# 3066H register map
File version: 1.0
Registers are 32-bit, access per field, reset 0x0 unless marked. A register's access mark holds for its fields unless they carry their own. Offsets are from the block's base; [hi:lo] are bit positions; {n}, {i} and the like mark numbered series.

## APT0 (part 2 of 2) — APT0 peripheral interface
Base 0x14A00000
Same registers: APT{n} {0x14A00000+0x1000*n} (n=1..15)
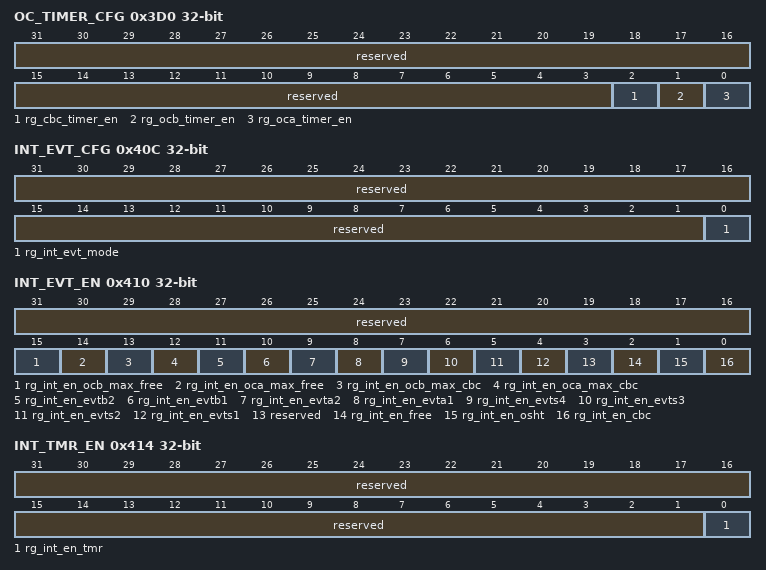
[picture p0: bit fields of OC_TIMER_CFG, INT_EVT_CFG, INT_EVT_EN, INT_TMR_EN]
0x3D0 OC_TIMER_CFG — OC_TIMER_CFG为保护计时器配置寄存器。支持写保护。
  [31:3] reserved ro — 保留。
  [2] rg_cbc_timer_en rw — CBC计时器使能。 0：不使能，OC_CBC_TIMER清零。 1：使能。OC_CBC_TIMER开始累计，当CBC保持0持续OC_CBC_TIMER_CLR后，OC_CBC_TIMER清零。
  [1] rg_ocb_timer_en rw — B路累计保护计时器使能。 0：不使能，OC_TIMER_B清零。 1：使能，OC_TIMER_B累计B路有效保护时间。
  [0] rg_oca_timer_en rw — A路累计保护计时器使能。 0：不使能，OC_TIMER_A清零。 1：使能，OC_TIMER_A累计A路有效保护时间。
0x3D4 OC_TIMER_A ro — OC_TIMER_A为APTx_PWMA累计保护计时器寄存器。
  [31:0] ro_oca_timer — A路累计的有效保护时间。记录因为保护导致PWM波发生变化的累计时间，包括输出1->0，输出0->1，输出0/1->高阻态。 0x0：累计保护持续了0个APTxCLK周期； 0x1：累计保护持续了1个APTxCLK周期； 0x2：累计保护持续了2个APTxCLK周期； … 0xFFFFFFFF：累计保护持续了大于等于4294967295个APTxCLK周期。
0x3D8 OC_TIMER_B ro — OC_TIMER_B为APTx_PWMB累计保护计时器寄存器。
  [31:0] ro_ocb_timer — B路累计的有效保护时间。记录因为保护导致PWM波发生变化的累计时间，包括输出1->0，输出0->1，输出0/1->高阻态。 0x0：累计保护持续了0个APTxCLK周期； 0x1：累计保护持续了1个APTxCLK周期； 0x2：累计保护持续了2个APTxCLK周期； … 0xFFFFFFFF：累计保护持续了大于等于4294967295个APTxCLK周期。
0x3DC OC_CBC_TIMER ro — OC_CBC_TIMER为CBC计时器寄存器。
  [31:0] ro_cbc_timer — CBC累计时间。累计CBC置位的时间。 0x0：累计CBC持续了0个APTxCLK周期； 0x1：累计CBC持续了1个APTxCLK周期； 0x2：累计CBC持续了2个APTxCLK周期； … 0xFFFFFFFF：累计CBC持续了大于等于4294967295个APTxCLK周期。
0x3E0 OC_CBC_TIMER_OSHT rw reset 0xFFFFFFFF — OC_CBC_TIMER_OSHT为CBC计时器配置寄存器。支持写保护。
  [31:0] rg_cbc_timer_osht — CBC计时器超过OC_CBC_TIMER_OSHT后，CBC无法被硬件周期性清零，只能由软件配置OC_SW_CLR清零。配置为0xFFFFFFFF时，不使能此功能。 0x0：0个APTxCLK周期； 0x1：1个APTxCLK周期； 0x2：2个APTxCLK周期； … 0xFFFFFFFE：4294967294个APTxCLK周期； 0xFFFFFFFF：不使能。
0x3E4 OC_CBC_TIMER_CLR rw reset 0xFFFFFFFF — OC_CBC_TIMER_CLR为CBC计时器自动清除配置寄存器。支持写保护。
  [31:0] rg_cbc_timer_clr — 当CBC保持0持续OC_CBC_TIMER_CLR后，OC_CBC_TIMER清零。配置为0xFFFFFFFF时，不使能此功能。 0x0：0个APTxCLK周期； 0x1：1个APTxCLK周期； 0x2：2个APTxCLK周期； … 0xFFFFFFFE：4294967294个APTxCLK周期； 0xFFFFFFFF：不清零。
0x40C INT_EVT_CFG — INT_EVT_CFG为事件中断配置寄存器。
  [31:1] reserved ro — 保留。
  [0] rg_int_evt_mode rw — 事件中断APTxEVTINT触发模式。本位域控制事件中断标志OC_EVT_FLAG触发置位的方式，进而改变APTxEVTINT触发模式。 0：上升沿触发； 1：高电平触发。
0x410 INT_EVT_EN — INT_EVT_EN为事件中断使能寄存器。
  [31:16] reserved ro — 保留。
  [15] rg_int_en_ocb_max_free rw — B路FREE最长保护事件中断使能。 0：OC_EVT_FLAG[ro_ocb_flag_max_free]不会触发事件中断APTxEVTINT； 1：OC_EVT_FLAG[ro_ocb_flag_max_free]会触发事件中断APTxEVTINT。
  [14] rg_int_en_oca_max_free rw — A路FREE最长保护事件中断使能。 0：OC_EVT_FLAG[ro_oca_flag_max_free]不会触发事件中断APTxEVTINT； 1：OC_EVT_FLAG[ro_oca_flag_max_free]会触发事件中断APTxEVTINT。
  [13] rg_int_en_ocb_max_cbc rw — B路CBC最长保护事件中断使能。 0：OC_EVT_FLAG[ro_ocb_flag_max_cbc]不会触发事件中断APTxEVTINT； 1：OC_EVT_FLAG[ro_ocb_flag_max_cbc]会触发事件中断APTxEVTINT。
  [12] rg_int_en_oca_max_cbc rw — A路CBC最长保护事件中断使能。 0：OC_EVT_FLAG[ro_oca_flag_max_cbc]不会触发事件中断APTxEVTINT； 1：OC_EVT_FLAG[ro_oca_flag_max_cbc]会触发事件中断APTxEVTINT。
  [11] rg_int_en_evtb2 rw — EMEVTB2事件中断使能。 0：OC_EVT_FLAG[ro_oc_flag_evtb2]不会触发事件中断APTxEVTINT； 1：OC_EVT_FLAG[ro_oc_flag_evtb2]会触发事件中断APTxEVTINT。
  [10] rg_int_en_evtb1 rw — EMEVTB1事件中断使能。 0：OC_EVT_FLAG[ro_oc_flag_evtb1]不会触发事件中断APTxEVTINT； 1：OC_EVT_FLAG[ro_oc_flag_evtb1]会触发事件中断APTxEVTINT。
  [9] rg_int_en_evta2 rw — EMEVTA2事件中断使能。 0：OC_EVT_FLAG[ro_oc_flag_evta2]不会触发事件中断APTxEVTINT； 1：OC_EVT_FLAG[ro_oc_flag_evta2]会触发事件中断APTxEVTINT。
  [8] rg_int_en_evta1 rw — EMEVTA1事件中断使能。 0：OC_EVT_FLAG[ro_oc_flag_evta1]不会触发事件中断APTxEVTINT； 1：OC_EVT_FLAG[ro_oc_flag_evta1]会触发事件中断APTxEVTINT。
  [7] rg_int_en_evts4 rw — SYSEVT4事件中断使能。 0：OC_EVT_FLAG[ro_oc_flag_evts4]不会触发事件中断APTxEVTINT； 1：OC_EVT_FLAG[ro_oc_flag_evts4]会触发事件中断APTxEVTINT。
  [6] rg_int_en_evts3 rw — SYSEVT3事件中断使能。 0：OC_EVT_FLAG[ro_oc_flag_evts3]不会触发事件中断APTxEVTINT； 1：OC_EVT_FLAG[ro_oc_flag_evts3]会触发事件中断APTxEVTINT。
  [5] rg_int_en_evts2 rw — SYSEVT2事件中断使能。 0：OC_EVT_FLAG[ro_oc_flag_evts2]不会触发事件中断APTxEVTINT； 1：OC_EVT_FLAG[ro_oc_flag_evts2]会触发事件中断APTxEVTINT。
  [4] rg_int_en_evts1 rw — SYSEVT1事件中断使能。 0：OC_EVT_FLAG[ro_oc_flag_evts1]不会触发事件中断APTxEVTINT； 1：OC_EVT_FLAG[ro_oc_flag_evts1]会触发事件中断APTxEVTINT。
  [3] reserved ro — 保留。
  [2] rg_int_en_free rw — FREE事件中断使能。 0：OC_EVT_FLAG[ro_oc_flag_free]不会触发事件中断APTxEVTINT； 1：OC_EVT_FLAG[ro_oc_flag_free]会触发事件中断APTxEVTINT。
  [1] rg_int_en_osht rw — OSHT事件中断使能。 0：OC_EVT_FLAG[ro_oc_flag_osht]不会触发事件中断APTxEVTINT； 1：OC_EVT_FLAG[ro_oc_flag_osht]会触发事件中断APTxEVTINT。
  [0] rg_int_en_cbc rw — CBC事件中断使能。 0：OC_EVT_FLAG[ro_oc_flag_cbc]不会触发事件中断APTxEVTINT； 1：OC_EVT_FLAG[ro_oc_flag_cbc]会触发事件中断APTxEVTINT。
0x414 INT_TMR_EN — INT_TMR_EN为定时中断使能寄存器。
  [31:1] reserved ro — 保留。
  [0] rg_int_en_tmr rw — 定时中断APTxTMRINT的使能位。 0：不使能； 1：使能。
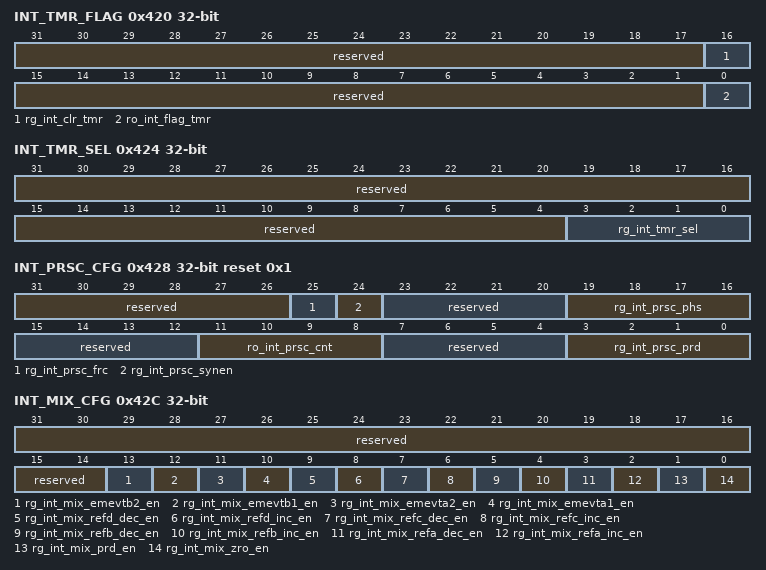
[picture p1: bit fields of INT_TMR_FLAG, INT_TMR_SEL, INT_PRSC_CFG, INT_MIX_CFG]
0x420 INT_TMR_FLAG — INT_TMR_FLAG为定时中断标志寄存器。
  [31:17] reserved ro — 保留。
  [16] rg_int_clr_tmr rw write-1-clears — 定时中断APTxTMRINT的中断清除位，写1清零。 0：写0无效； 1：写1有效。
  [15:1] reserved ro — 保留。
  [0] ro_int_flag_tmr ro — 定时中断APTxTMRINT的中断标志位。 0：APTxTMRINT无效； 1：APTxTMRINT有效。
0x424 INT_TMR_SEL — INT_TMR_SEL为定时中断的触发源选择寄存器。
  [31:4] reserved ro — 保留。
  [3:0] rg_int_tmr_sel rw — 定时中断APTxTMRINT的触发源选择。 0x1：CNT_ZERO有效； 0x2：CNT_PRD有效； 0x3：CNT_ZRO或CNT_PRD有效； 0x4：CNT_REFA有效且TCCNT计数方向递增； 0x5：CNT_REFA有效且TCCNT计数方向递减； 0x6：CNT_REFB有效且TCCNT计数方向递增； 0x7：CNT_REFB有效且TCCNT计数方向递减； 0x8：CNT_REFC有效且TCCNT计数方向递增； 0x9：CNT_REFC有效且TCCNT计数方向递减； 0xA：CNT_REFD有效且TCCNT计数方向递增； 0xB：CNT_REFD有效且TCCNT计数方向递减； 0xC：TMRINT_MIX有效； 其他：保留。
0x428 INT_PRSC_CFG reset 0x1 — INT_PRSC_CFG为定时中断缩减配置寄存器。
  [31:26] reserved ro — 保留。
  [25] rg_int_prsc_frc rw write-1-clears — 定时中断缩减计数器强制加1。 0：写0无效； 1：写1有效。
  [24] rg_int_prsc_synen rw — 定时中断缩减计数器的同步使能。 0：不使能； 1：使能。
  [23:20] reserved ro — 保留。
  [19:16] rg_int_prsc_phs rw — 定时中断缩减计数器的同步值。
  [15:12] reserved ro — 保留。
  [11:8] ro_int_prsc_cnt ro — 定时中断缩减计数器的计数值。
  [7:4] reserved ro — 保留。
  [3:0] rg_int_prsc_prd rw — 定时中断的缩减比例。 0x1：每发生1次有效的定时中断触发源，就产生定时中断； 0x2：每发生2次有效的定时中断触发源，就产生定时中断； 0x3：每发生3次有效的定时中断触发源，就产生定时中断； … 0xF：每发生15次有效的定时中断触发源，就产生定时中断。 其他：保留。
0x42C INT_MIX_CFG — INT_MIX_CFG为TMRINT_MIX配置寄存器。
  [31:14] reserved ro — 保留。
  [13] rg_int_mix_emevtb2_en rw — 使能EMEVTB2触发TMRINT_MIX信号。 0：不使能； 1：使能。
  [12] rg_int_mix_emevtb1_en rw — 使能EMEVTB1触发TMRINT_MIX信号。 0：不使能； 1：使能。
  [11] rg_int_mix_emevta2_en rw — 使能EMEVTA2触发TMRINT_MIX信号。 0：不使能； 1：使能。
  [10] rg_int_mix_emevta1_en rw — 使能EMEVTA1触发TMRINT_MIX信号。 0：不使能； 1：使能。
  [9] rg_int_mix_refd_dec_en rw — 使能CNT_REFD有效且TCCNT计数方向递减触发TMRINT_MIX信号。 0：不使能； 1：使能。
  [8] rg_int_mix_refd_inc_en rw — 使能CNT_REFD有效且TCCNT计数方向递增触发TMRINT_MIX信号。 0：不使能； 1：使能。
  [7] rg_int_mix_refc_dec_en rw — 使能CNT_REFC有效且TCCNT计数方向递减触发TMRINT_MIX信号。 0：不使能； 1：使能。
  [6] rg_int_mix_refc_inc_en rw — 使能CNT_REFC有效且TCCNT计数方向递增触发TMRINT_MIX信号。 0：不使能； 1：使能。
  [5] rg_int_mix_refb_dec_en rw — 使能CNT_REFB有效且TCCNT计数方向递减触发TMRINT_MIX信号。 0：不使能； 1：使能。
  [4] rg_int_mix_refb_inc_en rw — 使能CNT_REFB有效且TCCNT计数方向递增触发TMRINT_MIX信号。 0：不使能； 1：使能。
  [3] rg_int_mix_refa_dec_en rw — 使能CNT_REFA有效且TCCNT计数方向递减触发TMRINT_MIX信号。 0：不使能； 1：使能。
  [2] rg_int_mix_refa_inc_en rw — 使能CNT_REFA有效且TCCNT计数方向递增触发TMRINT_MIX信号。 0：不使能； 1：使能。
  [1] rg_int_mix_prd_en rw — 使能CNT_PRD触发TMRINT_MIX信号。 0：不使能； 1：使能。
  [0] rg_int_mix_zro_en rw — 使能CNT_ZERO触发TMRINT_MIX信号。 0：不使能； 1：使能。
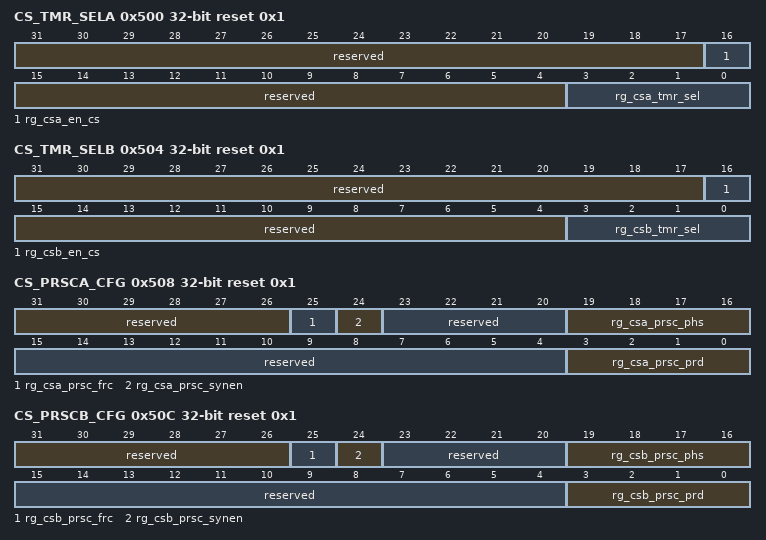
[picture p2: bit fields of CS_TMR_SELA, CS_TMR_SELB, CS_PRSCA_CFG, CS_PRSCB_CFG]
0x500 CS_TMR_SELA reset 0x1 — CS_TMR_SELA为APTxSOCA的触发源选择寄存器。
  [31:17] reserved ro — 保留。
  [16] rg_csa_en_cs rw — APTxSOCA的使能位。 0：不使能； 1：使能。
  [15:4] reserved ro — 保留。
  [3:0] rg_csa_tmr_sel rw — APTxSOCA的触发源选择。 0x0：EMEVTA1有效； 0x1：CNT_ZERO有效； 0x2：CNT_PRD有效； 0x3：CNT_ZERO或CNT_PRD有效； 0x4：CNT_REFA有效且TCCNT计数方向递增； 0x5：CNT_REFA有效且TCCNT计数方向递减； 0x6：CNT_REFB有效且TCCNT计数方向递增； 0x7：CNT_REFB有效且TCCNT计数方向递减； 0x8：CNT_REFC有效且TCCNT计数方向递增； 0x9：CNT_REFC有效且TCCNT计数方向递减； 0xA：CNT_REFD有效且TCCNT计数方向递增； 0xB：CNT_REFD有效且TCCNT计数方向递减； 0xC：SOCA_MIX有效； 其他：保留。
0x504 CS_TMR_SELB reset 0x1 — CS_TMR_SELB为APTxSOCB的触发源选择寄存器。
  [31:17] reserved ro — 保留。
  [16] rg_csb_en_cs rw — APTxSOCB的使能位。 0：不使能； 1：使能。
  [15:4] reserved ro — 保留。
  [3:0] rg_csb_tmr_sel rw — APTxSOCB的触发源选择。 0x0：EMEVTB1有效； 0x1：CNT_ZERO有效； 0x2：CNT_PRD有效； 0x3：CNT_ZERO或CNT_PRD有效； 0x4：CNT_REFA有效且TCCNT计数方向递增； 0x5：CNT_REFA有效且TCCNT计数方向递减； 0x6：CNT_REFB有效且TCCNT计数方向递增； 0x7：CNT_REFB有效且TCCNT计数方向递减； 0x8：CNT_REFC有效且TCCNT计数方向递增； 0x9：CNT_REFC有效且TCCNT计数方向递减； 0xA：CNT_REFD有效且TCCNT计数方向递增； 0xB：CNT_REFD有效且TCCNT计数方向递减； 0xC：SOCB_MIX有效； 其他：保留。
0x508 CS_PRSCA_CFG reset 0x1 — CS_PRSCA_CFG为APTxSOCA缩减配置寄存器。
  [31:26] reserved ro — 保留。
  [25] rg_csa_prsc_frc rw write-1-clears — APTxSOCA缩减计数器强制加1。 0：写0无效； 1：写1有效。
  [24] rg_csa_prsc_synen rw — APTxSOCA缩减计数器的同步使能。 0：不使能； 1：使能。
  [23:20] reserved ro — 保留。
  [19:16] rg_csa_prsc_phs rw — APTxSOCA缩减计数器的同步值。
  [15:4] reserved ro — 保留。
  [3:0] rg_csa_prsc_prd rw — APTxSOCA的缩减比例。 0x1：每发生1次有效的APTxSOCA的触发源，就产生APTxSOCA； 0x2：每发生2次有效的APTxSOCA的触发源，就产生APTxSOCA； 0x3：每发生3次有效的APTxSOCA的触发源，就产生APTxSOCA； … 0xF：每发生15次有效的APTxSOCA的触发源，就产生APTxSOCA。 其他：保留。
0x50C CS_PRSCB_CFG reset 0x1 — CS_PRSCB_CFG为APTxSOCB缩减配置寄存器。
  [31:26] reserved ro — 保留。
  [25] rg_csb_prsc_frc rw write-1-clears — APTxSOCB缩减计数器强制加1。 0：写0无效； 1：写1有效。
  [24] rg_csb_prsc_synen rw — APTxSOCB缩减计数器的同步使能。 0：不使能； 1：使能。
  [23:20] reserved ro — 保留。
  [19:16] rg_csb_prsc_phs rw — APTxSOCB缩减计数器的同步值。
  [15:4] reserved ro — 保留。
  [3:0] rg_csb_prsc_prd rw — APTxSOCB的缩减比例。 0x1：每发生1次有效的APTxSOCB的触发源，就产生APTxSOCB； 0x2：每发生2次有效的APTxSOCB的触发源，就产生APTxSOCB； 0x3：每发生3次有效的APTxSOCB的触发源，就产生APTxSOCB； … 0xF：每发生15次有效的APTxSOCB的触发源，就产生APTxSOCB。 其他：保留。
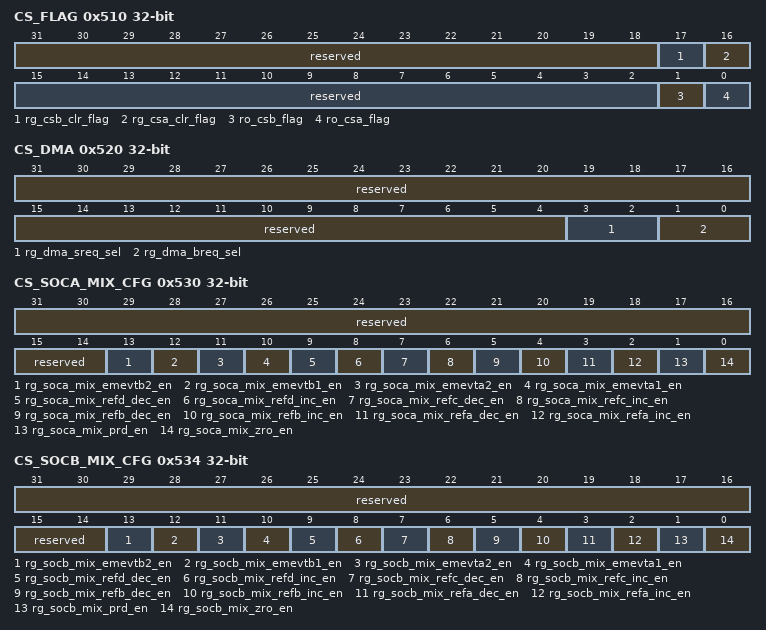
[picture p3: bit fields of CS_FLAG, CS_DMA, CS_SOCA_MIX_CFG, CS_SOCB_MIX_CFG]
0x510 CS_FLAG — CS_FLAG为APTxSOCA/APTxSOCB标志寄存器。
  [31:18] reserved ro — 保留。
  [17] rg_csb_clr_flag rw write-1-clears — APTxSOCB标志清除位，写1清零。 0：写0无效； 1：写1有效。
  [16] rg_csa_clr_flag rw write-1-clears — APTxSOCA标志清除位，写1清零。 0：写0无效； 1：写1有效。
  [15:2] reserved ro — 保留。
  [1] ro_csb_flag ro — APTxSOCB的标志位。 0：没有产生APTxSOCB； 1：已经产生APTxSOCB。
  [0] ro_csa_flag ro — APTxSOCA的标志位。 0：没有产生APTxSOCA； 1：已经产生APTxSOCA。
0x520 CS_DMA — CS_DMA为DMA请求配置寄存器。
  [31:4] reserved ro — 保留。
  [3:2] rg_dma_sreq_sel rw — DMA Single请求的触发源选择。 01：TRIGA信号有效； 10：TRIGB信号有效； 其他：禁止产生DMA Single请求。
  [1:0] rg_dma_breq_sel rw — DMA Burst请求的源头选择。 01：TRIGA信号有效； 10：TRIGB信号有效； 其他：禁止产生DMA Burst请求。
0x530 CS_SOCA_MIX_CFG — CS_SOCA_MIX_CFG为SOCA_MIX配置寄存器。
  [31:14] reserved ro — 保留。
  [13] rg_soca_mix_emevtb2_en rw — 使能EMEVTB2触发SOCA_MIX信号。 0：不使能； 1：使能。
  [12] rg_soca_mix_emevtb1_en rw — 使能EMEVTB1触发SOCA_MIX信号。 0：不使能； 1：使能。
  [11] rg_soca_mix_emevta2_en rw — 使能EMEVTA2触发SOCA_MIX信号。 0：不使能； 1：使能。
  [10] rg_soca_mix_emevta1_en rw — 使能EMEVTA1触发SOCA_MIX信号。 0：不使能； 1：使能。
  [9] rg_soca_mix_refd_dec_en rw — 使能CNT_REFD有效且TCCNT计数方向递减触发SOCA_MIX信号。 0：不使能； 1：使能。
  [8] rg_soca_mix_refd_inc_en rw — 使能CNT_REFD有效且TCCNT计数方向递增触发SOCA_MIX信号。 0：不使能； 1：使能。
  [7] rg_soca_mix_refc_dec_en rw — 使能CNT_REFC有效且TCCNT计数方向递减触发SOCA_MIX信号。 0：不使能； 1：使能。
  [6] rg_soca_mix_refc_inc_en rw — 使能CNT_REFC有效且TCCNT计数方向递增触发SOCA_MIX信号。 0：不使能； 1：使能。
  [5] rg_soca_mix_refb_dec_en rw — 使能CNT_REFB有效且TCCNT计数方向递减触发SOCA_MIX信号。 0：不使能； 1：使能。
  [4] rg_soca_mix_refb_inc_en rw — 使能CNT_REFB有效且TCCNT计数方向递增触发SOCA_MIX信号。 0：不使能； 1：使能。
  [3] rg_soca_mix_refa_dec_en rw — 使能CNT_REFA有效且TCCNT计数方向递减触发SOCA_MIX信号。 0：不使能； 1：使能。
  [2] rg_soca_mix_refa_inc_en rw — 使能CNT_REFA有效且TCCNT计数方向递增触发SOCA_MIX信号。 0：不使能； 1：使能。
  [1] rg_soca_mix_prd_en rw — 使能CNT_PRD触发SOCA_MIX信号。 0：不使能； 1：使能。
  [0] rg_soca_mix_zro_en rw — 使能CNT_ZERO触发SOCA_MIX信号。 0：不使能； 1：使能。
0x534 CS_SOCB_MIX_CFG — CS_SOCB_MIX_CFG为SOCB_MIX配置寄存器。
  [31:14] reserved ro — 保留。
  [13] rg_socb_mix_emevtb2_en rw — 使能EMEVTB2触发SOCB_MIX信号。 0：不使能； 1：使能。
  [12] rg_socb_mix_emevtb1_en rw — 使能EMEVTB1触发SOCB_MIX信号。 0：不使能； 1：使能。
  [11] rg_socb_mix_emevta2_en rw — 使能EMEVTA2触发SOCB_MIX信号。 0：不使能； 1：使能。
  [10] rg_socb_mix_emevta1_en rw — 使能EMEVTA1触发SOCB_MIX信号。 0：不使能； 1：使能。
  [9] rg_socb_mix_refd_dec_en rw — 使能CNT_REFD有效且TCCNT计数方向递减触发SOCB_MIX信号。 0：不使能； 1：使能。
  [8] rg_socb_mix_refd_inc_en rw — 使能CNT_REFD有效且TCCNT计数方向递增触发SOCB_MIX信号。 0：不使能； 1：使能。
  [7] rg_socb_mix_refc_dec_en rw — 使能CNT_REFC有效且TCCNT计数方向递减触发SOCB_MIX信号。 0：不使能； 1：使能。
  [6] rg_socb_mix_refc_inc_en rw — 使能CNT_REFC有效且TCCNT计数方向递增触发SOCB_MIX信号。 0：不使能； 1：使能。
  [5] rg_socb_mix_refb_dec_en rw — 使能CNT_REFB有效且TCCNT计数方向递减触发SOCB_MIX信号。 0：不使能； 1：使能。
  [4] rg_socb_mix_refb_inc_en rw — 使能CNT_REFB有效且TCCNT计数方向递增触发SOCB_MIX信号。 0：不使能； 1：使能。
  [3] rg_socb_mix_refa_dec_en rw — 使能CNT_REFA有效且TCCNT计数方向递减触发SOCB_MIX信号。 0：不使能； 1：使能。
  [2] rg_socb_mix_refa_inc_en rw — 使能CNT_REFA有效且TCCNT计数方向递增触发SOCB_MIX信号。 0：不使能； 1：使能。
  [1] rg_socb_mix_prd_en rw — 使能CNT_PRD触发SOCB_MIX信号。 0：不使能； 1：使能。
  [0] rg_socb_mix_zro_en rw — 使能CNT_ZERO触发SOCB_MIX信号。 0：不使能； 1：使能。
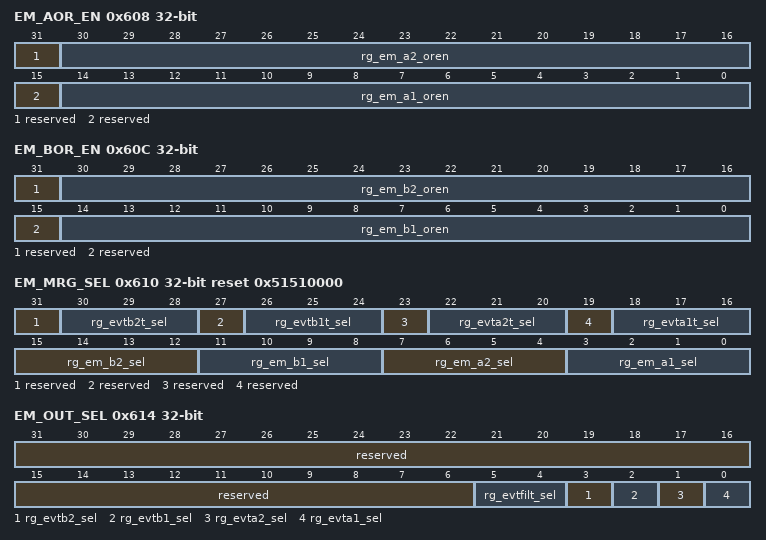
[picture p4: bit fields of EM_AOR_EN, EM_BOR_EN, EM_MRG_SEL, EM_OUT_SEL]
0x608 EM_AOR_EN — EM_AOR_EN为事件管理组合输入选择寄存器A。支持写保护。
  [31] reserved ro — 保留。
  [30:16] rg_em_a2_oren rw — TRIP_OR_A2的触发源选择，每个比特对应一个信号。 bit[30]：代表TRIP15的使能位； bit[29]：代表TRIP14的使能位； bit[28]：代表TRIP13的使能位； bit[27]：代表TRIP12的使能位； bit[26]：代表TRIP11的使能位； bit[25]：代表TRIP10的使能位； bit[24]：代表TRIP9的使能位； bit[23]：代表TRIP8的使能位； bit[22]：代表TRIP7的使能位； bit[21]：代表TRIP6的使能位； bit[20]：代表TRIP5的使能位； bit[19]：代表TRIP4的使能位； bit[18]：代表TRIP3的使能位； bit[17]：代表TRIP2的使能位； bit[16]：代表TRIP1的使能位； 其他比特无效，应配置为0。 当相应的比特为1时，代表对应的信号参与逻辑或； 当相应的比特为0时，代表对应的信号不参与逻辑或。
  [15] reserved ro — 保留。
  [14:0] rg_em_a1_oren rw — TRIP_OR_A1的触发源选择，每个比特对应一个信号。 bit[14]：代表TRIP15的使能位； bit[13]：代表TRIP14的使能位； bit[12]：代表TRIP13的使能位； bit[11]：代表TRIP12的使能位； bit[10]：代表TRIP11的使能位； bit[9]：代表TRIP10的使能位； bit[8]：代表TRIP9的使能位； bit[7]：代表TRIP8的使能位； bit[6]：代表TRIP7的使能位； bit[5]：代表TRIP6的使能位； bit[4]：代表TRIP5的使能位； bit[3]：代表TRIP4的使能位； bit[2]：代表TRIP3的使能位； bit[1]：代表TRIP2的使能位； bit[0]：代表TRIP1的使能位； 其他比特无效，应配置为0。 当相应的比特为1时，代表对应的信号参与逻辑或； 当相应的比特为0时，代表对应的信号不参与逻辑或。
0x60C EM_BOR_EN — EM_BOR_EN为事件管理组合输入选择寄存器B。支持写保护。
  [31] reserved ro — 保留。
  [30:16] rg_em_b2_oren rw — TRIP_OR_B2的触发源选择，每个比特对应一个信号。 bit[30]：代表TRIP15的使能位； bit[29]：代表TRIP14的使能位； bit[28]：代表TRIP13的使能位； bit[27]：代表TRIP12的使能位； bit[26]：代表TRIP11的使能位； bit[25]：代表TRIP10的使能位； bit[24]：代表TRIP9的使能位； bit[23]：代表TRIP8的使能位； bit[22]：代表TRIP7的使能位； bit[21]：代表TRIP6的使能位； bit[20]：代表TRIP5的使能位； bit[19]：代表TRIP4的使能位； bit[18]：代表TRIP3的使能位； bit[17]：代表TRIP2的使能位； bit[16]：代表TRIP1的使能位；其他比特无效，应配置为0。 当相应的比特为1时，代表对应的信号参与逻辑或； 当相应的比特为0时，代表对应的信号不参与逻辑或。
  [15] reserved ro — 保留。
  [14:0] rg_em_b1_oren rw — TRIP_OR_B1的触发源选择，每个比特对应一个信号。 bit[14]：代表TRIP15的使能位； bit[13]：代表TRIP14的使能位； bit[12]：代表TRIP13的使能位； bit[11]：代表TRIP12的使能位； bit[10]：代表TRIP11的使能位； bit[9]：代表TRIP10的使能位； bit[8]：代表TRIP9的使能位； bit[7]：代表TRIP8的使能位； bit[6]：代表TRIP7的使能位； bit[5]：代表TRIP6的使能位； bit[4]：代表TRIP5的使能位； bit[3]：代表TRIP4的使能位； bit[2]：代表TRIP3的使能位； bit[1]：代表TRIP2的使能位； bit[0]：代表TRIP1的使能位；其他比特无效，应配置为0。 当相应的比特为1时，代表对应的信号参与逻辑或； 当相应的比特为0时，代表对应的信号不参与逻辑或。
0x610 EM_MRG_SEL reset 0x51510000 — EM_MRG_SEL为事件管理输入选择寄存器。支持写保护。
  [31] reserved ro — 保留。
  [30:28] rg_evtb2t_sel rw — EMEVTB2_TEMP有效（高电平有效）的条件选择。 0x1：EMEVTB1_SRC为高电平； 0x2：EMEVTB1_SRC为高电平，且EMEVTB2_SRC为低电平； 0x3：EMEVTB1_SRC为高电平，且EMEVTB2_SRC为高电平； 0x4：EMEVTB1_SRC为低电平，且EMEVTB2_SRC为高电平； 0x5：EMEVTB2_SRC为高电平； 其他：EMEVTB2_TEMP输出低电平。
  [27] reserved ro — 保留。
  [26:24] rg_evtb1t_sel rw — EMEVTB1_TEMP有效（高电平有效）的条件选择。 0x1：EMEVTB1_SRC为高电平； 0x2：EMEVTB1_SRC为高电平，且EMEVTB2_SRC为低电平； 0x3：EMEVTB1_SRC为高电平，且EMEVTB2_SRC为高电平； 0x4：EMEVTB1_SRC为低电平，且EMEVTB2_SRC为高电平； 0x5：EMEVTB2_SRC为高电平； 其他：EMEVTB1_TEMP输出低电平。
  [23] reserved ro — 保留。
  [22:20] rg_evta2t_sel rw — EMEVTA2_TEMP有效（高电平有效）的条件选择。 0x1：EMEVTA1_SRC为高电平； 0x2：EMEVTA1_SRC为高电平，且EMEVTA2_SRC为低电平； 0x3：EMEVTA1_SRC为高电平，且EMEVTA2_SRC为高电平； 0x4：EMEVTA1_SRC为低电平，且EMEVTA2_SRC为高电平； 0x5：EMEVTA2_SRC为高电平； 其他：EMEVTA2_TEMP输出低电平。
  [19] reserved ro — 保留。
  [18:16] rg_evta1t_sel rw — EMEVTA1_TEMP有效（高电平有效）的条件选择。 0x1：EMEVTA1_SRC为高电平； 0x2：EMEVTA1_SRC为高电平，且EMEVTA2_SRC为低电平； 0x3：EMEVTA1_SRC为高电平，且EMEVTA2_SRC为高电平； 0x4：EMEVTA1_SRC为低电平，且EMEVTA2_SRC为高电平； 0x5：EMEVTA2_SRC为高电平； 其他：EMEVTA1_TEMP输出低电平。
  [15:12] rg_em_b2_sel rw — EMEVTB2_SRC触发源选择。 0x0：TRIP1； 0x1：TRIP2； 0x2：TRIP3； 0x3：TRIP4； 0x4：TRIP5； 0x5：TRIP6； 0x6：TRIP7； 0x7：TRIP8； 0x8：TRIP9； 0x9：TRIP10； 0xA：TRIP11； 0xB：TRIP12； 0xC：TRIP13； 0xD：TRIP14； 0xE：TRIP15； 0xF：TRIP_OR_B2； 其他：EMEVTB2_SRC输出低电平。
  [11:8] rg_em_b1_sel rw — EMEVTB1_SRC触发源选择。 0x0：TRIP1； 0x1：TRIP2； 0x2：TRIP3； 0x3：TRIP4； 0x4：TRIP5； 0x5：TRIP6； 0x6：TRIP7； 0x7：TRIP8； 0x8：TRIP9； 0x9：TRIP10； 0xA：TRIP11； 0xB：TRIP12； 0xC：TRIP13； 0xD：TRIP14； 0xE：TRIP15； 0xF：TRIP_OR_B1； 其他：EMEVTB1_SRC输出低电平。
  [7:4] rg_em_a2_sel rw — EMEVTA2_SRC触发源选择。 0x0：TRIP1； 0x1：TRIP2； 0x2：TRIP3； 0x3：TRIP4； 0x4：TRIP5； 0x5：TRIP6； 0x6：TRIP7； 0x7：TRIP8； 0x8：TRIP9； 0x9：TRIP10； 0xA：TRIP11； 0xB：TRIP12； 0xC：TRIP13； 0xD：TRIP14； 0xE：TRIP15； 0xF：TRIP_OR_A2； 其他：EMEVTA2_SRC输出低电平。
  [3:0] rg_em_a1_sel rw — EMEVTA1_SRC触发源选择。 0x0：TRIP1； 0x1：TRIP2； 0x2：TRIP3； 0x3：TRIP4； 0x4：TRIP5； 0x5：TRIP6； 0x6：TRIP7； 0x7：TRIP8； 0x8：TRIP9； 0x9：TRIP10； 0xA：TRIP11； 0xB：TRIP12； 0xC：TRIP13； 0xD：TRIP14； 0xE：TRIP15； 0xF：TRIP_OR_A1； 其他：EMEVTA1_SRC输出低电平。
0x614 EM_OUT_SEL — EM_OUT_SEL为事件管理输出选择寄存器。支持写保护。
  [31:6] reserved ro — 保留。
  [5:4] rg_evtfilt_sel rw — EMEVTFILT的触发源选择。 00：EMEVTA1_TEMP； 01：EMEVTA2_TEMP； 10：EMEVTB1_TEMP； 11：EMEVTB2_TEMP。
  [3] rg_evtb2_sel rw — EMEVTB2的触发源选择。 0：EMEVTB2_TEMP； 1：EMEVTFILT。
  [2] rg_evtb1_sel rw — EMEVTB1的触发源选择。 0：EMEVTB1_TEMP； 1：EMEVTFILT。
  [1] rg_evta2_sel rw — EMEVTA2的触发源选择。 0：EMEVTA2_TEMP； 1：EMEVTFILT。
  [0] rg_evta1_sel rw — EMEVTA1的触发源选择。 0：EMEVTA1_TEMP； 1：EMEVTFILT。
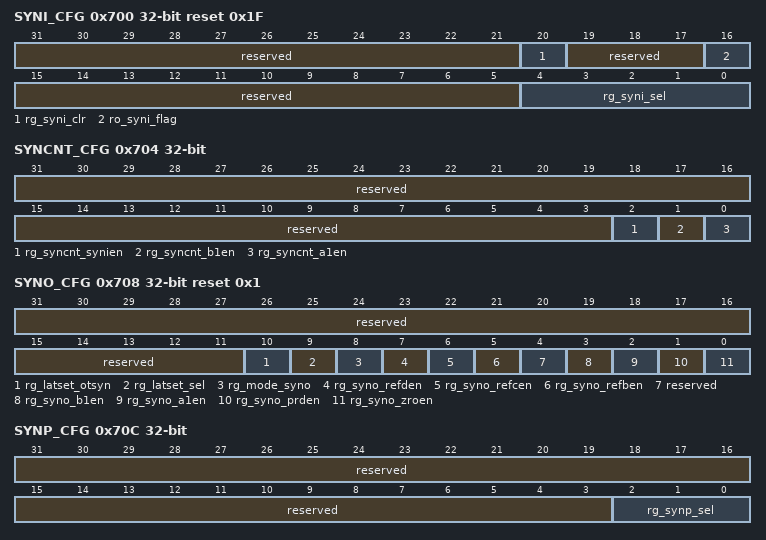
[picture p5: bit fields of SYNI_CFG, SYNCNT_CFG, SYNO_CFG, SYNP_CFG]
0x700 SYNI_CFG reset 0x1F — SYNI_CFG为同步输入配置寄存器。
  [31:21] reserved ro — 保留。
  [20] rg_syni_clr rw write-1-clears — APTxSYNCI的标志清除位，写1清零。 0：写0无效； 1：写1清除APTxSYNCI的标志位ro_syni_flag。
  [19:17] reserved ro — 保留。
  [16] ro_syni_flag ro — APTxSYNCI的标志位。 0：APTxSYNCI无效； 1：APTxSYNCI有效。
  [15:5] reserved ro — 保留。
  [4:0] rg_syni_sel rw — APTxSYNCI的触发源选择。 0x0：APT0SYNCO； 0x1：APT1SYNCO； 0x2：APT2SYNCO； 0x3：APT3SYNCO； 0x4：APT4SYNCO； 0x5：APT5SYNCO； 0x6：APT6SYNCO； 0x7：APT7SYNCO； 0x8：APT8SYNCO； 0x9：CAPM0SYNCO； 0xA：CAPM1SYNCO； 0xB：CAPM2SYNCO； 0xC：TRIP4； 0xD：TRIP5； 0xE：APT9SYNCO； 0xF：APT10SYNCO； 0x10：APT11SYNCO； 0x11：APT12SYNCO； 0x12：APT13SYNCO； 0x13：APT14SYNCO； 0x14：APT15SYNCO； 其他：禁止产生APTxSYNCI。
0x704 SYNCNT_CFG — SYNCNT_CFG为计数器同步信号配置寄存器。
  [31:3] reserved ro — 保留。
  [2] rg_syncnt_synien rw — 当APTxSYNCI有效时，选择是否产生APTCNTSYNC。 0：不使能； 1：使能。
  [1] rg_syncnt_b1en rw — 当EMEVTB1有效时，选择是否产生APTCNTSYNC。 0：不使能； 1：使能。
  [0] rg_syncnt_a1en rw — 当EMEVTA1有效时，选择是否产生APTCNTSYNC。 0：不使能； 1：使能。
0x708 SYNO_CFG reset 0x1 — SYNO_CFG为同步输出配置寄存器。
  [31:11] reserved ro — 保留。
  [10] rg_latset_otsyn rw write-1-clears — 控制同步输出单次锁存器置位。 0：写0无效； 1：写1有效。
  [9] rg_latset_sel rw — 当选择单次同步输出模式，选择同步输出单次锁存器置位的条件。 0：向SYNO_CFG[rg_latset_otsyn]写1时置位； 1：向GLB_LOAD[rg_latset_otgld]写1时置位。
  [8] rg_mode_syno rw — 同步输出的模式选择。 0：单次同步输出； 1：不限次数同步输出。
  [7] rg_syno_refden rw — 当CNT_REFD有效时，选择是否产生APTxSYNCO。 0：不使能； 1：使能。
  [6] rg_syno_refcen rw — 当CNT_REFC有效时，选择是否产生APTxSYNCO。 0：不使能； 1：使能。
  [5] rg_syno_refben rw — 当CNT_REFB有效时，选择是否产生APTxSYNCO。 0：不使能； 1：使能。
  [4] reserved ro — 保留。
  [3] rg_syno_b1en rw — 当EMEVTB1有效时，选择是否产生APTxSYNCO。 0：不使能； 1：使能。
  [2] rg_syno_a1en rw — 当EMEVTA1有效时，选择是否产生APTxSYNCO。 0：不使能； 1：使能。
  [1] rg_syno_prden rw — 当CNT_PRD有效时，选择是否产生APTxSYNCO。 0：不使能； 1：使能。
  [0] rg_syno_zroen rw — 当CNT_ZERO有效时，选择是否产生APTxSYNCO。 0：不使能； 1：使能。
0x70C SYNP_CFG — SYNP_CFG为外设同步配置寄存器。
  [31:3] reserved ro — 保留。
  [2:0] rg_synp_sel rw — 外设同步输出的源头选择。 000：禁止； 001：TC计数器等于0； 010：TC计数器等于计数周期； 011：TC计数器等于计数参考值C，且计数方向递增； 100：TC计数器等于计数参考值C，且计数方向递减； 101：TC计数器等于计数参考值D，且计数方向递增； 110：TC计数器等于计数参考值D，且计数方向递减； 111：禁止。
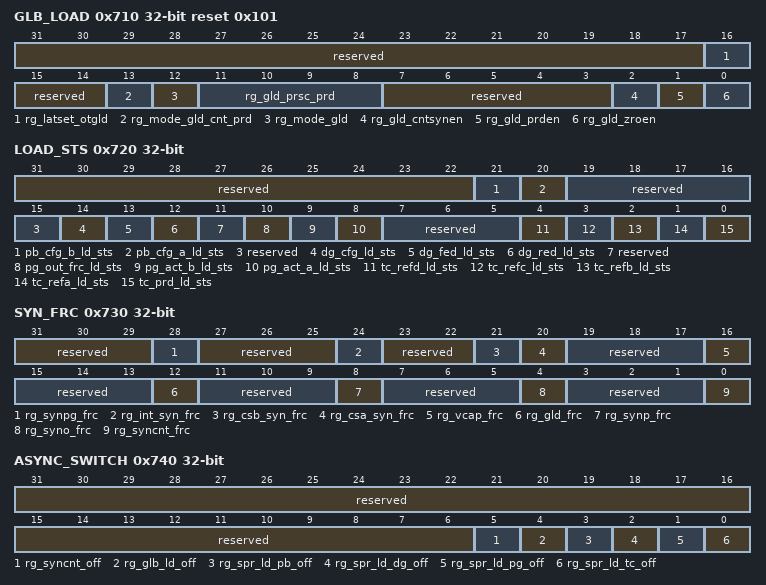
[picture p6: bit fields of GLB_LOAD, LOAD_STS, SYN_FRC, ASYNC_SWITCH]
0x710 GLB_LOAD reset 0x101 — GLB_LOAD为全局加载配置寄存器。支持LINK。
  [31:17] reserved ro — 保留。
  [16] rg_latset_otgld rw write-1-clears — 控制全局加载单次锁存器置位。 0：写0无效； 1：写1有效。
  [15:14] reserved ro — 保留。
  [13] rg_mode_gld_cnt_prd rw — 全局加载TC_PRD寄存器的模式选择。 0：全局加载信号生效时立即加载TC_PRD； 1：全局加载信号生效时，如果不在CNT_ZERO时刻，等待下一次CNT_ZERO再加载TC_PRD。如果在CNT_ZERO时刻，立即加载TC_PRD。 注意：此模式选择只有在使能了TC_PRD寄存器的缓存和全局加载才有效果。
  [12] rg_mode_gld rw — 全局加载的模式选择。 0：单次加载； 1：不限次数加载。
  [11:8] rg_gld_prsc_prd rw — 全局加载信号缩减计数器的缩减比例。 0x0：不产生glb_ld； 0x1：每发生1次有效的全局加载触发信号，就产生glb_ld； 0x2：每发生2次有效的全局加载触发信号，就产生glb_ld； 0x3：每发生3次有效的全局加载触发信号，就产生glb_ld； … 0xF：每发生15次有效的全局加载触发信号，就产生glb_ld。 其他：保留。
  [7:3] reserved ro — 保留。
  [2] rg_gld_cntsynen rw — 使能APTCNTSYNC作为全局加载触发信号。 0：不使能； 1：使能。
  [1] rg_gld_prden rw — 使能CNT_PRD作为全局加载触发信号。 0：不使能； 1：使能。
  [0] rg_gld_zroen rw — 使能CNT_ZERO作为全局加载触发信号。 0：不使能； 1：使能。
0x720 LOAD_STS ro — LOAD_STS为缓存状态寄存器。
  [31:22] reserved — 保留。
  [21] pb_cfg_b_ld_sts — 当使能了PB_CFG_B寄存器的缓存，指示PB_CFG_B寄存器的缓存状态。 0：缓存寄存器空； 1：缓存寄存器满。
  [20] pb_cfg_a_ld_sts — 当使能了PB_CFG_A寄存器的缓存，指示PB_CFG_A寄存器的缓存状态。 0：缓存寄存器空； 1：缓存寄存器满。
  [19:15] reserved — 保留。
  [14] dg_cfg_ld_sts — 当使能了DG_CFG寄存器的缓存，指示DG_CFG寄存器的缓存状态。 0：缓存寄存器空； 1：缓存寄存器满。
  [13] dg_fed_ld_sts — 当使能了DG_FED寄存器的缓存，指示DG_FED寄存器的缓存状态。 0：缓存寄存器空； 1：缓存寄存器满。
  [12] dg_red_ld_sts — 当使能了DG_RED寄存器的缓存，指示DG_RED寄存器的缓存状态。 0：缓存寄存器空； 1：缓存寄存器满。
  [11] reserved — 保留。
  [10] pg_out_frc_ld_sts — 当使能了PG_OUT_FRC寄存器的缓存，指示PG_OUT_FRC寄存器的缓存状态。 0：缓存寄存器空； 1：缓存寄存器满。
  [9] pg_act_b_ld_sts — 当使能了PG_ACT_B寄存器的缓存，指示PG_ACT_B寄存器的缓存状态。 0：缓存寄存器空； 1：缓存寄存器满。
  [8] pg_act_a_ld_sts — 当使能了PG_ACT_A寄存器的缓存，指示PG_ACT_A寄存器的缓存状态。 0：缓存寄存器空； 1：缓存寄存器满。
  [7:5] reserved — 保留。
  [4] tc_refd_ld_sts — 当使能了TC_REFD寄存器的缓存，指示TC_REFD寄存器的缓存状态。 0：缓存寄存器空； 1：缓存寄存器满。
  [3] tc_refc_ld_sts — 当使能了TC_REFC寄存器的缓存，指示TC_REFC寄存器的缓存状态。 0：缓存寄存器空； 1：缓存寄存器满。
  [2] tc_refb_ld_sts — 当使能了TC_REFB寄存器的缓存，指示TC_REFB寄存器的缓存状态。 0：缓存寄存器空； 1：缓存寄存器满。
  [1] tc_refa_ld_sts — 当使能了TC_REFA寄存器的缓存，指示TC_REFA寄存器的缓存状态。 0：缓存寄存器空； 1：缓存寄存器满。
  [0] tc_prd_ld_sts — 当使能了TC_PRD寄存器的缓存，指示TC_PRD寄存器的缓存状态。 0：缓存寄存器空； 1：缓存寄存器满。
0x730 SYN_FRC — SYN_FRC为软件强制寄存器。支持LINK。
  [31:29] reserved ro — 保留。
  [28] rg_synpg_frc rw write-1-clears — 强制产生一个PG_ACT_A/PG_ACT_B寄存器的独立加载的触发信号。 0：写0无效； 1：写1有效。
  [27:25] reserved ro — 保留。
  [24] rg_int_syn_frc rw write-1-clears — 强制定时中断缩减计数器更新成INT_PRSC_CFG[rg_int_prsc_phs]中的值。 0：写0无效； 1：写1有效。
  [23:22] reserved ro — 保留。
  [21] rg_csb_syn_frc rw write-1-clears — 强制产生一次APTxSOCB的触发源。 0：写0无效； 1：写1有效。
  [20] rg_csa_syn_frc rw write-1-clears — 强制产生一次APTxSOCA的触发源。 0：写0无效； 1：写1有效。
  [19:17] reserved ro — 保留。
  [16] rg_vcap_frc rw write-1-clears — 强制产生一个谷底捕获重启的触发事件。 0：无效； 1：有效。
  [15:13] reserved ro — 保留。
  [12] rg_gld_frc rw write-1-clears — 强制产生一次全局加载信号的触发信号。 0：写0无效； 1：写1有效。
  [11:9] reserved ro — 保留。
  [8] rg_synp_frc rw write-1-clears — 强制产生一个外设同步事件。 0：无效； 1：有效。
  [7:5] reserved ro — 保留。
  [4] rg_syno_frc rw write-1-clears — 强制产生一次APTxSYNCO的触发源。 0：写0无效； 1：写1有效。
  [3:1] reserved ro — 保留。
  [0] rg_syncnt_frc rw write-1-clears — 强制产生一个APTCNTSYNC信号。 0：写0无效； 1：写1有效。
0x740 ASYNC_SWITCH — ASYNC_SWITCH为软件异步开关配置寄存器。支持LINK。
  [31:6] reserved ro — 保留。
  [5] rg_syncnt_off rw — 是否开启计数器同步。 0：开启； 1：关闭。
  [4] rg_glb_ld_off rw — 是否开启缓存全局加载。 0：开启； 1：关闭。
  [3] rg_spr_ld_pb_off rw — 是否开启PB子模块缓存寄存器的独立加载。 0：开启； 1：关闭。
  [2] rg_spr_ld_dg_off rw — 是否开启DG子模块缓存寄存器的独立加载。 0：开启； 1：关闭。
  [1] rg_spr_ld_pg_off rw — 是否开启PG子模块缓存寄存器的独立加载。 0：开启； 1：关闭。
  [0] rg_spr_ld_tc_off rw — 是否开启TC子模块缓存寄存器的独立加载。 0：开启； 1：关闭。
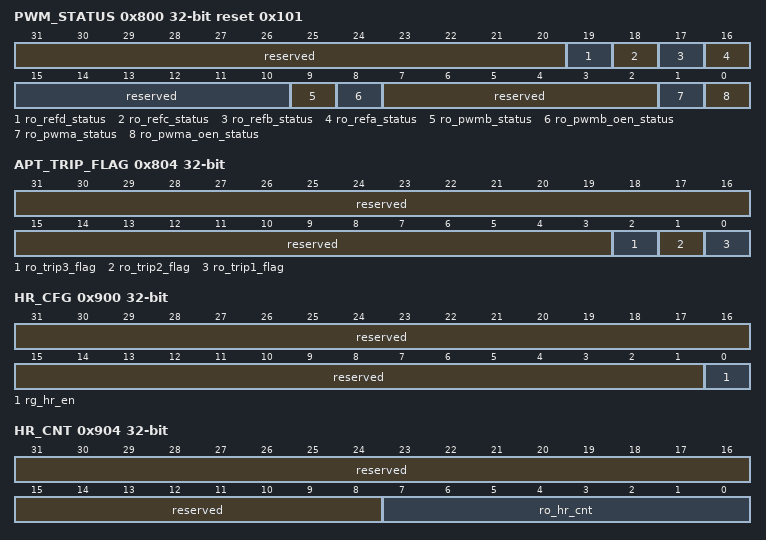
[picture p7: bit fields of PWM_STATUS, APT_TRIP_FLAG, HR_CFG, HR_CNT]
0x800 PWM_STATUS ro reset 0x101 — PWM_STATUS为PWM输出状态寄存器。
  [31:20] reserved — 保留。
  [19] ro_refd_status — 参考点D有效时，翻转一次。
  [18] ro_refc_status — 参考点C有效时，翻转一次。
  [17] ro_refb_status — 参考点B有效时，翻转一次。
  [16] ro_refa_status — 参考点A有效时，翻转一次。
  [15:10] reserved — 保留。
  [9] ro_pwmb_status — APT_PWMB输出状态，只有当PWM_STATUS[ro_pwmb_oen_status]为0时，该位域的值才有效。 0：APT_PWMB输出为低电平； 1：APT_PWMB输出为高电平。
  [8] ro_pwmb_oen_status — APT_PWMB_OEN输出状态。 0：APT_PWMB输出状态查询PWM_STATUS[ro_pwmb_status]位域； 1：APT_PWMB输出为高阻态。
  [7:2] reserved — 保留。
  [1] ro_pwma_status — APT_PWMA输出状态，只有当PWM_STATUS[ro_pwma_oen_status]为0时，该位域的值才有效。 0：APT_PWMA输出为低电平； 1：APT_PWMA输出为高电平。
  [0] ro_pwma_oen_status — APT_PWMA_OEN输出状态。 0：APT_PWMA输出状态查询PWM_STATUS[ro_pwma_status]位域； 1：APT_PWMA输出为高阻态。
0x804 APT_TRIP_FLAG ro — APT_TRIP_FLAG为TRIP事件标志寄存器。
  [31:3] reserved — 保留。
  [2] ro_trip3_flag — TRIP3事件标志。 0：APT的输入TRIP3事件为低电平； 1：APT的输入TRIP3事件为高电平。
  [1] ro_trip2_flag — TRIP2事件标志。 0：APT的输入TRIP2事件为低电平； 1：APT的输入TRIP2事件为高电平。
  [0] ro_trip1_flag — TRIP1事件标志。 0：APT的输入TRIP1事件为低电平； 1：APT的输入TRIP1事件为高电平。
0x900 HR_CFG ro — HR_CFG为高精度PWM配置寄存器。支持写保护。
  [31:1] reserved — 保留。
  [0] rg_hr_en — 高精度PWM使能。 0：不使能； 1：使能。
0x904 HR_CNT ro — HR_CNT为高精度PWM计数器。
  [31:8] reserved — 保留。
  [7:0] ro_hr_cnt — 高精度PWM计数器实时值。
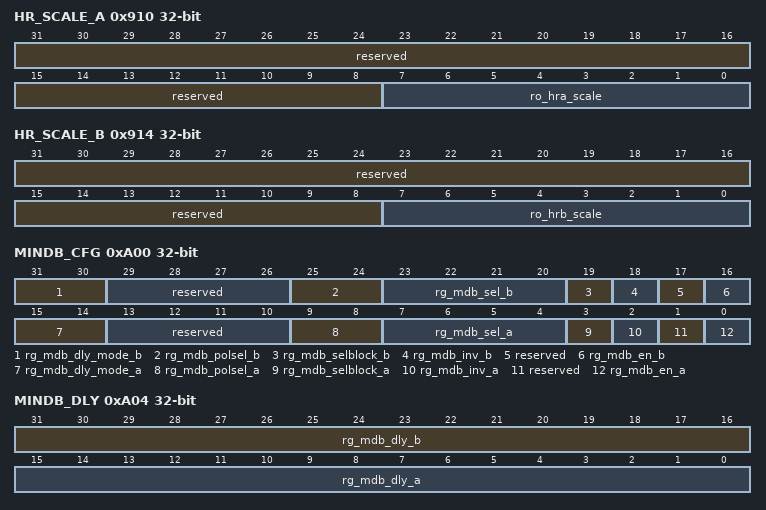
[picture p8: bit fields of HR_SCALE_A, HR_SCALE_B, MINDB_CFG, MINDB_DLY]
0x910 HR_SCALE_A ro — HR_SCALE_A为A通道高精度Scale寄存器。
  [31:8] reserved — 保留。
  [7:0] ro_hra_scale — A通道高精度刻度数。
0x914 HR_SCALE_B ro — HR_SCALE_B为B通道高精度Scale寄存器。
  [31:8] reserved — 保留。
  [7:0] ro_hrb_scale — B通道高精度刻度数。
0xA00 MINDB_CFG — MINDB_CFG为Minimum dead band最小死区配置寄存器。
  [31:30] rg_mdb_dly_mode_b rw — 选择BLOCKB信号延时模式。 00：下降沿延时； 01：上升沿延时； 10：双沿延时； 11：滤波。
  [29:26] reserved ro — 保留。
  [25:24] rg_mdb_polsel_b rw — 选择PWMB路信号的处理方式配置rg_mdb_selblock_b选择BLOCKA或者BLOCKB。 00：选择（!BLOCKA或者BLOCKB） & OC_PWMB； 01：选择（BLOCKA或者BLOCKB） | OC_PWMB； 10：不处理； 11：保留。
  [23:20] rg_mdb_sel_b rw — 选择B路的参考信号。 0x0：低精度PWMB路信号，OC_PWMB_NO_HR； 0x1：MINDB_XBAR_OUT1； 0x2：MINDB_XBAR_OUT2； ... 0xF：MINDB_XBAR_OUT15。
  [19] rg_mdb_selblock_b rw — 选择BLOCKA还是BLOCKB信号与PWMB路信号做处理，配置rg_mdb_polsel_b选择处理方式。 0：选择BLOCKB信号作为B路的参考信号，与PWMB路信号做处理； 1：选择BLOCKA信号作为B路的参考信号，与PWMB路信号做处理。 配置rg_mindbb_polsel以选择PWMB路信号的处理方式。
  [18] rg_mdb_inv_b rw — B路的参考信号是否取反。 0：B路的参考信号不取反； 1：B路的参考信号取反。
  [17] reserved ro — 保留。
  [16] rg_mdb_en_b rw — B路MINDB是否使能。 0：B路MINDB（Minimum dead band）最小死区功能不使能； 1：B路最小死区功能使能。
  [15:14] rg_mdb_dly_mode_a rw — 选择BLOCKA信号延时模式。 00：下降沿延时； 01：上升沿延时； 10：双沿延时； 11：滤波。
  [13:10] reserved ro — 保留。
  [9:8] rg_mdb_polsel_a rw — 选择PWMA路信号的处理方式，配置rg_mdb_selblock_a选择BLOCKA或者BLOCKB。 00：选择（!BLOCKA或者BLOCKB） & OC_PWMA； 01：选择（BLOCKA或者BLOCKB） | OC_PWMA； 10：不处理； 11：保留。
  [7:4] rg_mdb_sel_a rw — 选择A路的参考信号。 0x0：低精度PWMA路信号，OC_PWMA_NO_HR； 0x1：MINDB_XBAR_OUT1； 0x2：MINDB_XBAR_OUT2； ... 0xF：MINDB_XBAR_OUT15。
  [3] rg_mdb_selblock_a rw — 选择BLOCKA还是BLOCKB信号与PWMA路信号做处理，配置rg_mdb_polsel_a选择处理方式。 0：选择BLOCKA信号作为A路的参考信号，与PWMA路信号做处理； 1：选择BLOCKB信号作为A路的参考信号，与PWMA路信号做处理。 配置rg_mindbb_polsel以选择PWMA路信号的处理方式。
  [2] rg_mdb_inv_a rw — A路的参考信号是否取反。 0：A路的参考信号不取反； 1：A路的参考信号取反。
  [1] reserved ro — 保留。
  [0] rg_mdb_en_a rw — A路MINDB是否使能。 0：A路MINDB（Minimum dead band）最小死区功能不使能； 1：A路最小死区功能使能。
0xA04 MINDB_DLY rw — MINDB_DLY为Minimum dead band最小死区延时配置寄存器。
  [31:16] rg_mdb_dly_b — B路最小死区延时配置。 0x0：0个APTxCLK； 0x1：1个APTxCLK； 0x2：2个APTxCLK； … 0xFFFF：65535个APTxCLK。
  [15:0] rg_mdb_dly_a — A路最小死区延时配置。 0x0：0个APTxCLK； 0x1：1个APTxCLK； 0x2：2个APTxCLK； … 0xFFFF：65535个APTxCLK。
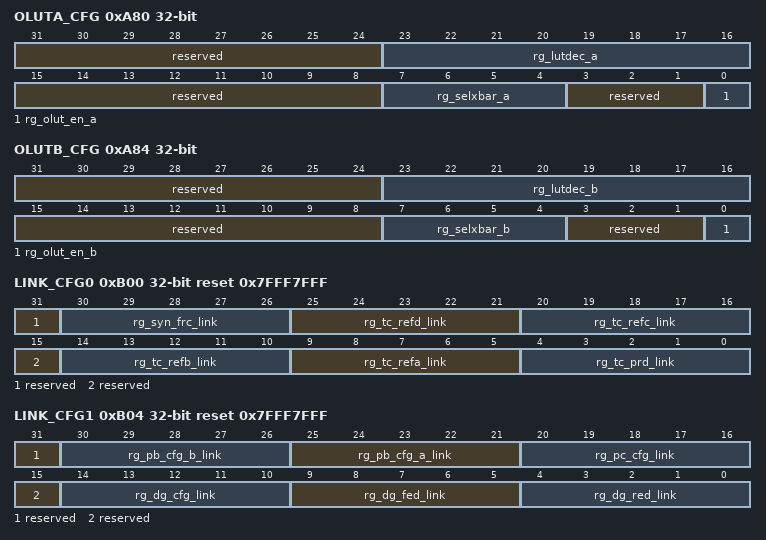
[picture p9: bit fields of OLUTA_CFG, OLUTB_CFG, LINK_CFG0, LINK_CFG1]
0xA80 OLUTA_CFG — OLUTA_CFG为Output LUTA输出查找表配置寄存器。
  [31:24] reserved ro — 保留。
  [23:16] rg_lutdec_a rw — LUTA输入（IN3，IN2，IN1）的查找表项。8bit对应输入的8种组合。 示例： 0x1：输入（IN3，IN2，IN1）=（0，0，0），对应LUTA输出1，其他输入组合时均输出0； 0x81：（IN3，IN2，IN1）输入=（1，1，1）或（0，0，0），对应LUTA输出1，其他输入组合时均输出0。
  [15:8] reserved ro — 保留。
  [7:4] rg_selxbar_a rw — 选择OLUT XBAR的16个输出中的1个，作为LUTA的IN3输入。 0x0：选择OLUT XBAR Output1，作为LUTA的IN3输入； 0x1：选择OLUT XBAR Output2，作为LUTA的IN3输入； … 0xF：选择OLUT XBAR Output16，作为LUTA的IN3输入； 其他：LUTA的IN3为0。
  [3:1] reserved ro — 保留。
  [0] rg_olut_en_a rw — A路OLUT是否使能。 0：PWMA路输出直通，旁路LUTA； 1：PWMA路输出被LUTA驱动。
0xA84 OLUTB_CFG — OLUTB_CFG为Output LUTB输出查找表配置寄存器。
  [31:24] reserved ro — 保留。
  [23:16] rg_lutdec_b rw — LUTB输入（IN3，IN2，IN1）的查找表项。8bit对应输入的8种组合。 示例： 0x1：输入（IN3，IN2，IN1）=（0，0，0），对应LUTB输出1，其他输入组合时均输出0； 0x81：（IN3，IN2，IN1）输入=（1，1，1）或（0，0，0），对应LUTB输出1，其他输入组合时均输出0。
  [15:8] reserved ro — 保留。
  [7:4] rg_selxbar_b rw — 选择OLUT XBAR的16个输出中的1个，作为LUTB的IN3输入。 0x0：选择OLUT XBAR Output1，作为LUTB的IN3输入； 0x1：选择OLUT XBAR Output2，作为LUTB的IN3输入； … 0xF：选择OLUT XBAR Output16，作为LUTB的IN3输入； 其他：LUTB的IN3为0。
  [3:1] reserved ro — 保留。
  [0] rg_olut_en_b rw — B路OLUT是否使能。 0：PWMB路输出直通，旁路LUTB； 1：PWMB路输出被LUTB驱动。
0xB00 LINK_CFG0 reset 0x7FFF7FFF — LINK_CFG0为LINK配置0寄存器。
  [31] reserved ro — 保留。
  [30:26] rg_syn_frc_link rw — SYN_FRC寄存器LINK配置。 软件写如下配置APT的SYN_FRC寄存器会同时写当前APT的SYN_FRC寄存器。 0x0：LINK到APT0； 0x1：LINK到APT1； 0x2：LINK到APT2； … 最大值到最后一个APT，其他值保留； 0x1F：LINK不使能。
  [25:21] rg_tc_refd_link rw — TC_REFD寄存器LINK配置。 软件写如下配置APT的TC_REFD寄存器会同时写当前APT的TC_REFD寄存器。 0x0：LINK到APT0； 0x1：LINK到APT1； 0x2：LINK到APT2； … 最大值到最后一个APT，其他值保留； 0x1F：LINK不使能。
  [20:16] rg_tc_refc_link rw — TC_REFC寄存器LINK配置。 软件写如下配置APT的TC_REFC寄存器会同时写当前APT的TC_REFC寄存器。 0x0：LINK到APT0； 0x1：LINK到APT1； 0x2：LINK到APT2； … 最大值到最后一个APT，其他值保留； 0x1F：LINK不使能。
  [15] reserved ro — 保留。
  [14:10] rg_tc_refb_link rw — TC_REFB寄存器LINK配置。 软件写如下配置APT的TC_REFB寄存器会同时写当前APT的TC_REFB寄存器。 0x0：LINK到APT0； 0x1：LINK到APT1； 0x2：LINK到APT2； … 最大值到最后一个APT，其他值保留； 0x1F：LINK不使能。
  [9:5] rg_tc_refa_link rw — TC_REFA寄存器LINK配置。 软件写如下配置APT的TC_REFA寄存器会同时写当前APT的TC_REFA寄存器。 0x0：LINK到APT0； 0x1：LINK到APT1； 0x2：LINK到APT2； … 最大值到最后一个APT，其他值保留； 0x1F：LINK不使能。
  [4:0] rg_tc_prd_link rw — TC_PRD寄存器LINK配置。 软件写如下配置APT的TC_PRD寄存器会同时写当前APT的TC_PRD寄存器。 0x0：LINK到APT0； 0x1：LINK到APT1； 0x2：LINK到APT2； … 最大值到最后一个APT，其他值保留； 0x1F：LINK不使能。
0xB04 LINK_CFG1 reset 0x7FFF7FFF — LINK_CFG1为LINK配置1寄存器。
  [31] reserved ro — 保留。
  [30:26] rg_pb_cfg_b_link rw — PB_CFG_B寄存器LINK配置。 软件写如下配置APT的PB_CFG_B寄存器会同时写当前APT的PB_CFG_B寄存器。 0x0：LINK到APT0； 0x1：LINK到APT1； 0x2：LINK到APT2； … 最大值到最后一个APT，其他值保留； 0x1F：LINK不使能。
  [25:21] rg_pb_cfg_a_link rw — PB_CFG_A寄存器LINK配置。 软件写如下配置APT的PB_CFG_A寄存器会同时写当前APT的PB_CFG_A寄存器。 0x0：LINK到APT0； 0x1：LINK到APT1； 0x2：LINK到APT2； … 最大值到最后一个APT，其他值保留； 0x1F：LINK不使能。
  [20:16] rg_pc_cfg_link rw — PC_CFG寄存器LINK配置。 软件写如下配置APT的PC_CFG寄存器会同时写当前APT的PC_CFG寄存器。 0x0：LINK到APT0； 0x1：LINK到APT1； 0x2：LINK到APT2； … 最大值到最后一个APT，其他值保留； 0x1F：LINK不使能。
  [15] reserved ro — 保留。
  [14:10] rg_dg_cfg_link rw — DG_CFG寄存器LINK配置。 软件写如下配置APT的DG_CFG寄存器会同时写当前APT的DG_CFG寄存器。 0x0：LINK到APT0； 0x1：LINK到APT1； 0x2：LINK到APT2； … 最大值到最后一个APT，其他值保留； 0x1F：LINK不使能。
  [9:5] rg_dg_fed_link rw — DG_FED寄存器LINK配置。 软件写如下配置APT的DG_FED寄存器会同时写当前APT的DG_FED寄存器。 0x0：LINK到APT0； 0x1：LINK到APT1； 0x2：LINK到APT2； … 最大值到最后一个APT，其他值保留； 0x1F：LINK不使能。
  [4:0] rg_dg_red_link rw — DG_RED寄存器LINK配置。 软件写如下配置APT的DG_RED寄存器会同时写当前APT的DG_RED寄存器。 0x0：LINK到APT0； 0x1：LINK到APT1； 0x2：LINK到APT2； … 最大值到最后一个APT，其他值保留； 0x1F：LINK不使能。
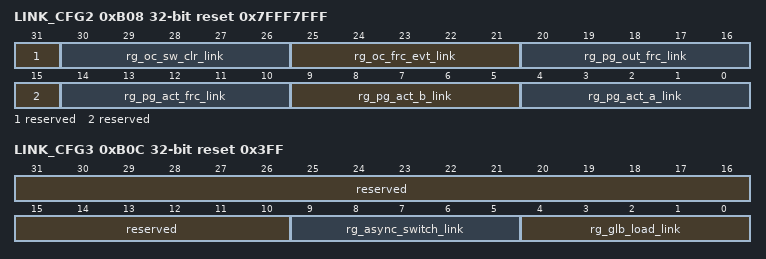
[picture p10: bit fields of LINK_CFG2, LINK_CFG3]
0xB08 LINK_CFG2 reset 0x7FFF7FFF — LINK_CFG2为LINK配置2寄存器。
  [31] reserved ro — 保留。
  [30:26] rg_oc_sw_clr_link rw — OC_SW_CLR寄存器LINK配置。 软件写如下配置APT的OC_SW_CLR寄存器会同时写当前APT的OC_SW_CLR寄存器。 0x0：LINK到APT0； 0x1：LINK到APT1； 0x2：LINK到APT2； … 最大值到最后一个APT，其他值保留； 0x1F：LINK不使能。
  [25:21] rg_oc_frc_evt_link rw — OC_FRC_EVT寄存器LINK配置。 软件写如下配置APT的OC_FRC_EVT寄存器会同时写当前APT的OC_FRC_EVT寄存器。 0x0：LINK到APT0； 0x1：LINK到APT1； 0x2：LINK到APT2； … 最大值到最后一个APT，其他值保留； 0x1F：LINK不使能。
  [20:16] rg_pg_out_frc_link rw — PG_OUT_FRC寄存器LINK配置。 软件写如下配置APT的PG_OUT_FRC寄存器会同时写当前APT的PG_OUT_FRC寄存器。 0x0：LINK到APT0； 0x1：LINK到APT1； 0x2：LINK到APT2； … 最大值到最后一个APT，其他值保留； 0x1F：LINK不使能。
  [15] reserved ro — 保留。
  [14:10] rg_pg_act_frc_link rw — PG_ACT_FRC寄存器LINK配置。 软件写如下配置APT的PG_ACT_FRC寄存器会同时写当前APT的PG_ACT_FRC寄存器。 0x0：LINK到APT0； 0x1：LINK到APT1； 0x2：LINK到APT2； … 最大值到最后一个APT，其他值保留； 0x1F：LINK不使能。
  [9:5] rg_pg_act_b_link rw — PG_ACT_B寄存器LINK配置。 软件写如下配置APT的PG_ACT_B寄存器会同时写当前APT的PG_ACT_B寄存器。 0x0：LINK到APT0； 0x1：LINK到APT1； 0x2：LINK到APT2； … 最大值到最后一个APT，其他值保留； 0x1F：LINK不使能。
  [4:0] rg_pg_act_a_link rw — PG_ACT_A寄存器LINK配置。 软件写如下配置APT的PG_ACT_A寄存器会同时写当前APT的PG_ACT_A寄存器。 0x0：LINK到APT0； 0x1：LINK到APT1； 0x2：LINK到APT2； … 最大值到最后一个APT，其他值保留； 0x1F：LINK不使能。
0xB0C LINK_CFG3 reset 0x3FF — LINK_CFG3为LINK配置3寄存器。
  [31:10] reserved ro — 保留。
  [9:5] rg_async_switch_link rw — ASYNC_SWITCH寄存器LINK配置。 软件写如下配置APT的ASYNC_SWITCH寄存器会同时写当前APT的ASYNC_SWITCH寄存器。 0x0：LINK到APT0； 0x1：LINK到APT1； 0x2：LINK到APT2； … 最大值到最后一个APT，其他值保留； 0x1F：LINK不使能。
  [4:0] rg_glb_load_link rw — GLB_LOAD寄存器LINK配置。 软件写如下配置APT的GLB_LOAD寄存器会同时写当前APT的GLB_LOAD寄存器。 0x0：LINK到APT0； 0x1：LINK到APT1； 0x2：LINK到APT2； … 最大值到最后一个APT，其他值保留； 0x1F：LINK不使能。
